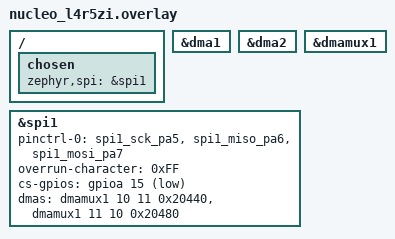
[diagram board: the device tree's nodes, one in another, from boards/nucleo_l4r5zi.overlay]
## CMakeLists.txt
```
# SPDX-License-Identifier: Apache-2.0

cmake_minimum_required(VERSION 3.20.0)
find_package(Zephyr REQUIRED HINTS $ENV{ZEPHYR_BASE})
project(spi_master)

target_sources(app PRIVATE src/main.c)
```

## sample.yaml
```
# SPDX-License-Identifier: Apache-2.0

sample:
  name: SPI Master with DMA
  description: |
    Demonstrates SPI master communication with DMA support on STM32 boards.
    Continuously sends messages to an SPI slave and displays the responses.

tests:
  sample.boards.st.spi_master:
    harness: console
    platform_allow:
      - nucleo_l4r5zi
    tags:
      - spi
      - stm32
      - dma
      - gpio
    vendor_allow:
      - st
    integration_platforms:
      - nucleo_l4r5zi
    harness_config:
      type: multi_line
      ordered: true
      regex:
        - "SPI Master Sample"
        - "SPI device ready"
        - "Starting SPI communication loop"
        - "TX string:"
```

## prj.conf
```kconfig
# SPDX-License-Identifier: Apache-2.0

# GPIO driver for CS control
CONFIG_GPIO=y

# SPI driver
CONFIG_SPI=y
CONFIG_SPI_ASYNC=y

# DMA support for efficient data transfer
CONFIG_DMA=y
CONFIG_DMA_STM32=y
CONFIG_SPI_STM32_DMA=y

# Logging
CONFIG_LOG=y
CONFIG_LOG_DEFAULT_LEVEL=2
CONFIG_PRINTK=y

# Increase main stack size for logging overhead
CONFIG_MAIN_STACK_SIZE=2048
```

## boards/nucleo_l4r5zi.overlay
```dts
/*
 * Copyright (c) 2025 Waqar Ahmed
 * SPDX-License-Identifier: Apache-2.0
 */

/ {
	chosen {
		zephyr,spi = &spi1;
	};
};

&dma1 {
	status = "okay";
};

&dma2 {
	status = "okay";
};

&dmamux1 {
	status = "okay";
};

spi_master: &spi1 {
	status = "okay";
	/* SPI1 default pins */
	pinctrl-0 = <&spi1_sck_pa5 &spi1_miso_pa6 &spi1_mosi_pa7>;
	pinctrl-names = "default";
	overrun-character = <0xFF>;
	cs-gpios = <&gpioa 15 GPIO_ACTIVE_LOW>;
	dmas = <&dmamux1 10 11 0x20440>,   /* SPI1_TX: slot 10, request 11, M2P+MINC */
	       <&dmamux1 11 10 0x20480>;   /* SPI1_RX: slot 11, request 10, P2M+MINC */
	dma-names = "tx", "rx";
};
```

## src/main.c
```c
/*
 * Copyright (c) 2025 Waqar Ahmed
 *
 * SPDX-License-Identifier: Apache-2.0
 */

#include <zephyr/kernel.h>
#include <zephyr/drivers/spi.h>
#include <zephyr/drivers/gpio.h>
#include <zephyr/devicetree.h>
#include <zephyr/logging/log.h>
#include <zephyr/sys/printk.h>
#include <string.h>

LOG_MODULE_REGISTER(spi_master_sample, LOG_LEVEL_DBG);

/* SPI device from devicetree */
#define SPI_NODE DT_NODELABEL(spi_master)

/* Message buffer size */
#define MSG_BUF_SIZE 32

/* Separate CS control struct for proper initialization */
static const struct spi_cs_control cs_ctrl = {
	.gpio = GPIO_DT_SPEC_GET(SPI_NODE, cs_gpios),
	.delay = 10,
	.cs_is_gpio = true,
};

/* SPI configuration */
static struct spi_config spi_cfg = {
	.frequency = 312500,
	.operation = SPI_WORD_SET(8) | SPI_TRANSFER_MSB | SPI_OP_MODE_MASTER,
	.slave = 0,
	.cs = cs_ctrl,
};

/**
 * @brief Print SPI configuration for debugging
 *
 * @param cfg Pointer to SPI configuration
 */
static void print_spi_config(const struct spi_config *cfg)
{
	LOG_INF("=== SPI Configuration ===");
	LOG_INF("Frequency: %u Hz", cfg->frequency);
	LOG_INF("Operation: 0x%08X", cfg->operation);
	LOG_INF("Slave: %u", cfg->slave);

	if (cfg->cs.cs_is_gpio) {
		LOG_INF("CS GPIO port: %p", cfg->cs.gpio.port);
		LOG_INF("CS GPIO pin: %u", cfg->cs.gpio.pin);
		LOG_INF("CS GPIO flags: 0x%04X", cfg->cs.gpio.dt_flags);
		LOG_INF("CS delay: %u us", cfg->cs.delay);
	}

	LOG_INF("========================");
}

/**
 * @brief Prepare transmission buffer with message and padding
 *
 * @param buf Buffer to prepare
 * @param buf_size Size of buffer
 * @param msg_number Message sequence number
 * @return Length of prepared message
 */
static size_t prepare_tx_buffer(uint8_t *buf, size_t buf_size, uint32_t msg_number)
{
	int msg_len;

	/* Format message */
	msg_len = snprintf((char *)buf, buf_size,
			   "Hello from master %u", msg_number);

	/* Pad remaining bytes with pattern for debugging */
	if (msg_len < buf_size) {
		memset(buf + msg_len, 0xAA, buf_size - msg_len);
	}

	return buf_size;
}

int main(void)
{
	const struct device *spi_dev;
	uint8_t tx_buf[MSG_BUF_SIZE];
	uint8_t rx_buf[MSG_BUF_SIZE];
	uint32_t msg_number = 0;
	struct spi_buf tx_spi_buf;
	struct spi_buf rx_spi_buf;
	struct spi_buf_set tx_set;
	struct spi_buf_set rx_set;
	int ret;

	LOG_INF("SPI Master Sample");

	/* Get SPI device from devicetree */
	spi_dev = DEVICE_DT_GET(SPI_NODE);
	if (!device_is_ready(spi_dev)) {
		LOG_ERR("SPI device not ready");
		return -ENODEV;
	}

	LOG_INF("SPI device ready");

	/* Print configuration for debugging */
	print_spi_config(&spi_cfg);

	/* Initialize SPI buffer structures */
	tx_spi_buf.buf = tx_buf;
	rx_spi_buf.buf = rx_buf;

	tx_set.buffers = &tx_spi_buf;
	tx_set.count = 1;

	rx_set.buffers = &rx_spi_buf;
	rx_set.count = 1;

	/* Wait for slave device to initialize */
	LOG_INF("Waiting for slave initialization...");
	k_sleep(K_SECONDS(2));

	LOG_INF("Starting SPI communication loop");

	while (1) {
		msg_number++;

		/* Prepare transmission buffer */
		size_t msg_len = prepare_tx_buffer(tx_buf, MSG_BUF_SIZE, msg_number);

		/* Set buffer lengths */
		tx_spi_buf.len = msg_len;
		rx_spi_buf.len = msg_len;

		/* Clear receive buffer */
		memset(rx_buf, 0, MSG_BUF_SIZE);

		LOG_DBG("[%lld ms] Sending message #%u", k_uptime_get(), msg_number);
		LOG_INF("TX string: [%s] Message Length: %d", tx_buf, msg_len);

		/* Perform SPI transaction */
		ret = spi_transceive(spi_dev, &spi_cfg, &tx_set, &rx_set);

		if (ret == 0) {
			/* Null-terminate for safe string printing */
			rx_buf[msg_len < MSG_BUF_SIZE ? msg_len : MSG_BUF_SIZE - 1] = '\0';
			LOG_INF("RX string: [%s] Message Length: %d", rx_buf, msg_len);
		} else {
			LOG_ERR("SPI transaction failed: %d", ret);
		}

		/* Wait before next transmission */
		k_sleep(K_SECONDS(1));
	}

	return 0;
}
```
